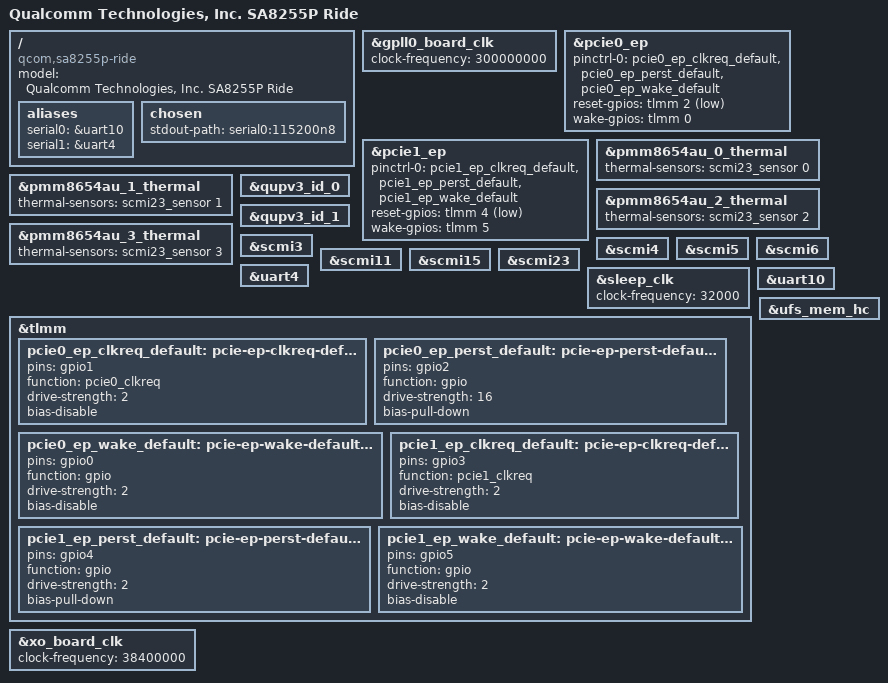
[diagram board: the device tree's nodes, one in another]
// SPDX-License-Identifier: BSD-3-Clause
/*
 * Copyright (c) Qualcomm Technologies, Inc. and/or its subsidiaries.
 */

/dts-v1/;

#include <dt-bindings/gpio/gpio.h>

#include "sa8255p.dtsi"
#include "sa8255p-pmics.dtsi"

/ {
	model = "Qualcomm Technologies, Inc. SA8255P Ride";
	compatible = "qcom,sa8255p-ride", "qcom,sa8255p";

	aliases {
		serial0 = &uart10;
		serial1 = &uart4;
	};

	chosen {
		stdout-path = "serial0:115200n8";
	};
};

&gpll0_board_clk {
	clock-frequency = <300000000>;
};

&pcie0_ep {
	pinctrl-names = "default";
	pinctrl-0 = <&pcie0_ep_clkreq_default &pcie0_ep_perst_default
		    &pcie0_ep_wake_default>;
	reset-gpios = <&tlmm 2 GPIO_ACTIVE_LOW>;
	wake-gpios = <&tlmm 0 GPIO_ACTIVE_HIGH>;
};

&pcie1_ep {
	pinctrl-names = "default";
	pinctrl-0 = <&pcie1_ep_clkreq_default &pcie1_ep_perst_default
		    &pcie1_ep_wake_default>;
	reset-gpios = <&tlmm 4 GPIO_ACTIVE_LOW>;
	wake-gpios = <&tlmm 5 GPIO_ACTIVE_HIGH>;
};

&pmm8654au_0_thermal {
	thermal-sensors = <&scmi23_sensor 0>;
};

&pmm8654au_1_thermal {
	thermal-sensors = <&scmi23_sensor 1>;
};

&pmm8654au_2_thermal {
	thermal-sensors = <&scmi23_sensor 2>;
};

&pmm8654au_3_thermal {
	thermal-sensors = <&scmi23_sensor 3>;
};

&qupv3_id_0 {
	status = "okay";
};

&qupv3_id_1 {
	status = "okay";
};

&scmi3 {
	status = "okay";
};

&scmi4 {
	status = "okay";
};

&scmi5 {
	status = "okay";
};

&scmi6 {
	status = "okay";
};

&scmi11 {
	status = "okay";
};

&scmi15 {
	status = "okay";
};

&scmi23 {
	status = "okay";
};

&sleep_clk {
	clock-frequency = <32000>;
};

&uart4 {
	status = "okay";
};

&uart10 {
	status = "okay";
};

&tlmm {
	pcie0_ep_clkreq_default: pcie-ep-clkreq-default-state {
		pins = "gpio1";
		function = "pcie0_clkreq";
		drive-strength = <2>;
		bias-disable;
	};

	pcie0_ep_perst_default: pcie-ep-perst-default-state {
		pins = "gpio2";
		function = "gpio";
		drive-strength = <16>;
		bias-pull-down;
	};

	pcie0_ep_wake_default: pcie-ep-wake-default-state {
		pins = "gpio0";
		function = "gpio";
		drive-strength = <2>;
		bias-disable;
	};

	pcie1_ep_clkreq_default: pcie-ep-clkreq-default-state {
		pins = "gpio3";
		function = "pcie1_clkreq";
		drive-strength = <2>;
		bias-disable;
	};

	pcie1_ep_perst_default: pcie-ep-perst-default-state {
		pins = "gpio4";
		function = "gpio";
		drive-strength = <2>;
		bias-pull-down;
	};

	pcie1_ep_wake_default: pcie-ep-wake-default-state {
		pins = "gpio5";
		function = "gpio";
		drive-strength = <2>;
		bias-disable;
	};
};

&ufs_mem_hc {
	status = "okay";
};

&xo_board_clk {
	clock-frequency = <38400000>;
};
